# H3 register map
Vendor: Allwinner; Series: H3; File version: 0.1
CPU: 0, little endian, MPU, no FPU, 0 interrupt priority bits
Registers are 32-bit, read-write, reset 0x0 unless marked. A register's access mark holds for its fields unless they carry their own. Offsets are from the block's base; lines under a group give offsets from that group; [hi:lo] are bit positions; {n}, {i} and the like mark numbered series; 'fields as' and 'values as' point back to an identical list; <NAME> marks a mode.

## Memory map
0x01C00000 System_Control
0x01C02000 DMA
0x01C03000 NDFC
0x01C06000 TSC
0x01C0C000 TCON0
0x01C0D000 TCON1
0x01C0F000 SD/MMC0
0x01C10000 SD/MMC1
0x01C11000 SD/MMC2
0x01C15000 CE_N
0x01C15800 CE_S
0x01C17000 MSGBOX
0x01C18000 SPINLOCK
0x01C1B000 USB_HCI1
0x01C1C000 USB_HCI2
0x01C1D000 USB_HCI3
0x01C1E000 SMC
0x01C20000 CCU
0x01C20800 PIO
0x01C20C00 TIMER
0x01C21000 OWA
0x01C21400 PWM
0x01C21800 KEY_ADC
0x01C22000 I2S/PCM_0
0x01C22400 I2S/PCM_1
0x01C22800 I2S/PCM_2
0x01C22C00 AC
0x01C23400 SMTA
0x01C25000 Thermal_Sensor
0x01C28000 UART0
0x01C28400 UART1
0x01C28800 UART2
0x01C28C00 UART3
0x01C2AC00 TWI0
0x01C2B000 TWI1
0x01C2B400 TWI2
0x01C2C400 SCR
0x01C30000 EMAC
0x01C60000 High_Speed_Timer
0x01C68000 SPI0
0x01C69000 SPI1
0x01CB0000 CSI0
0x01F00000 RTC
0x01F01800 TWD
0x01F01C00 CPUCFG
0x01F02000 CIR
0x01F02400 R_TWI
0x01F02800 R-UART
0x01F02C00 PIO

## Thermal_Sensor
Base 0x01C25000
0x00 THS_CTRL_REG0
  [15:0] SENSOR_ACQ0 — ADC acquire time CLK_IN/(N+1)
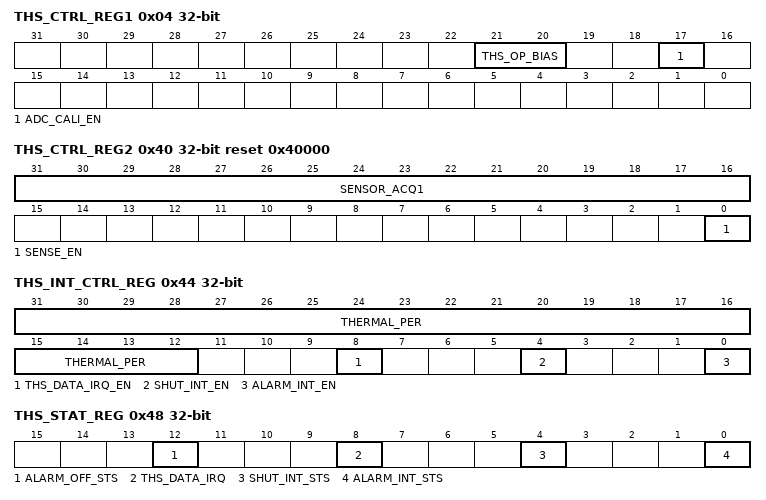
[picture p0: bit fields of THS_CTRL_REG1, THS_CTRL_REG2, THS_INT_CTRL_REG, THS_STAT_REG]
0x04 THS_CTRL_REG1
  [21:20] THS_OP_BIAS
  [17] ADC_CALI_EN — ADC Calibration 1: start Calibration, it is clear to 0 after calibration
    1=start Calibration, it is clear to 0 after calibration
0x14 ADC_CDAT_REG reset not defined
  [11:0] ADC_CDAT — ADC calibration data
0x40 THS_CTRL_REG2 reset 0x40000
  [31:16] SENSOR_ACQ1 — Sensor acquire time CLK_IN/(N+1)
  [0] SENSE_EN — Enable temperature measurement sensor 0:Disable 1:Enable
0x44 THS_INT_CTRL_REG
  [31:12] THERMAL_PER — 4096*(n+1)/CLK_IN
  [8] THS_DATA_IRQ_EN — Selects Temperature measurement data of sensor 0: No select 1: Select
    0=No_select; 1=Select
  [4] SHUT_INT_EN — Selects shutdown interrupt for sensor 0: No select 1: Select
    0=No_select; 1=Select
  [0] ALARM_INT_EN — Selects Alert interrupt for sensor 0: No select 1: Select
    0=No_select; 1=Select
0x48 THS_STAT_REG
  [12] ALARM_OFF_STS — Alarm interrupt off pending for sensor Write `1` to clear this interrupt or automatic clear if interrupt condition fails
  [8] THS_DATA_IRQ — _STS. Data interrupt status for sensor Write `1` to clear this interrupt or automatic clear if interrupt condition fails
  [4] SHUT_INT_STS — Shutdown interrupt status for sensor Write `1` to clear this interrupt or automatic clear if interrupt condition fails
  [0] ALARM_INT_STS — Alarm interrupt pending for sensor Write `1` to clear this interrupt or automatic clear if interrupt condition fails
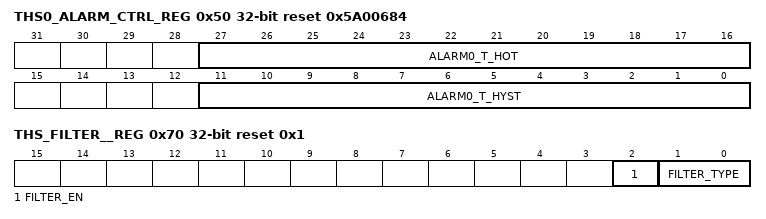
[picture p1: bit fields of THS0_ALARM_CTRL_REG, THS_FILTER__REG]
0x50 THS0_ALARM_CTRL_REG reset 0x5A00684
  [27:16] ALARM0_T_HOT — Thermal sensor0 Alarm Threshold for hot temperature
  [11:0] ALARM0_T_HYST — Thermal sensor0 Alarm threshold for hysteresis temperature
0x60 THS_SHUTDOWN_CTRL_REG reset 0x4E90000
  [27:16] SHUT0_T_HOT — Thermal sensor0 Shutdown Threshold for hot temperature
0x70 THS_FILTER__REG reset 0x1
  [2] FILTER_EN — Filter Enable 0: Disable 1: Enable
    0=Disable; 1=Enable
  [1:0] FILTER_TYPE — Average Filter Type 00: 2 01: 4 10: 8 11: 16
    0=_2; 1=_4; 2=_8; 3=_16
0x74 THS_CDATA__REG reset 0x800
  [11:0] THS_CDATA — Thermal Sensor calibration data
0x80 THS_DATA__REG
  [11:0] THS_DATA ro — Temperature measurement data of sensor

## CE_N
Base 0x01C15000
Same registers: CE_S 0x01C15800
0x00 CE_TDQ — Task Descriptor Address
  [31:0] TASK_DESCRIPTOR_QUEUE_ADDRESS
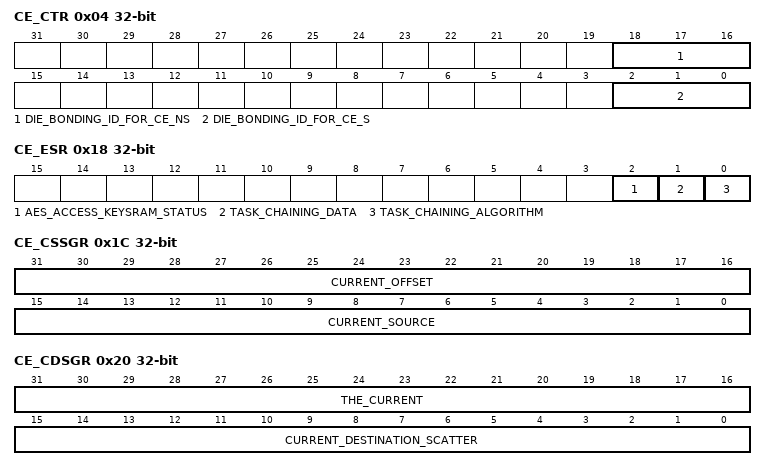
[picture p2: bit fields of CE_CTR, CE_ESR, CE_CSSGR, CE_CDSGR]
0x04 CE_CTR reset not defined — Gating Control Register
  [18:16] DIE_BONDING_ID_FOR_CE_NS ro, [2:0] DIE_BONDING_ID_FOR_CE_S ro
0x08 CE_ICR — Interrupt Control Register
  [0] TASK — Task chaining_interrupt_enable 0: interrupt disable 1: interrupt enable
    0=interrupt_disable; 1=interrupt_enable
0x0C CE_ISR — Interrupt Status Register
  [0] TASK — Task chaining_End_Pending 0: busy 1: task end It indicates that the processing of encrypt /signing or decrypt/verification has been completed . Notes: Write `1` to clear it.
    0=busy; 1=task end It indicates that the processing of encrypt /signing or decrypt/verification has been completed . Notes: Write `1` to clear it.
0x10 CE_TLR — Task Load Register
  [0] TASK_LOAD — When set , CE starts to load the configure of task from task descriptor queue and start to perform the task.
0x18 CE_ESR — Task Error type Register
  [2] AES_ACCESS_KEYSRAM_STATUS ro — AES_Access_Keysram_Status 0: AES could perform request if destination address is keysram. 1: AES couldn't perform request if destination address is not keysram. Notes: Write `1` to clear it.
    0=AES could perform request if destination address is keysram; 1=AES couldn't perform request if destination address is not keysram. Notes: Write `1` to clear it.
  [1] TASK_CHAINING_DATA ro — Task chaining data length error When the bit is 1,indicate that the configure of data length is error
  [0] TASK_CHAINING_ALGORITHM ro — Task chaining algorithm error When the bit is 1,indicate that CE is not support the algorithm
0x1C CE_CSSGR — Current Source Scatter Group Register
  [31:16] CURRENT_OFFSET ro — The current offset in src adr These bits indicate that the offset of source address
  [15:0] CURRENT_SOURCE ro — The current source scatter number When a task is divided to some scatter(max is 8 scatter), these bits indicate that the scatter is executing for source data
0x20 CE_CDSGR (reset mask 0xFFFF) — Current Destination Scatter Group Register
  [31:16] THE_CURRENT ro — 0 The current offset in dst adr These bits indicate that the offset of destination address
  [15:0] CURRENT_DESTINATION_SCATTER ro — The current destination scatter number When a task is divided to some scatter(max is 8 scatter), these bits indicate that the scatter is executing for destination data
0x24 CE_CSAR — Current Source Address Register
  [31:0] CURRENT ro — Current source address of the executing task
0x28 CE_CDAR — Current Destination Address Register
  [31:0] CURRENT ro — Current destination address of the executing task
0x2C CE_TPR — Throughput Register
  [31:0] IT_INDICATES_THE_THROUGHPUT — It indicates the throughput of data from the whole processing. Notes: Write `0` to clear it by CPU.

## Licence text in the file
questionable
